# TC37XPD register map
Vendor: Infineon; Series: ATVMC; File version: 100
CPU: other r0p0, little endian, MPU, FPU, vendor SysTick, 4 interrupt priority bits
Registers are 32-bit, read-write, reset 0x0 unless marked. A register's access mark holds for its fields unless they carry their own. Offsets are from the block's base; [hi:lo] are bit positions; {n}, {i} and the like mark numbered series.

## GETH (part 2 of 7)
Base 0xF001D000
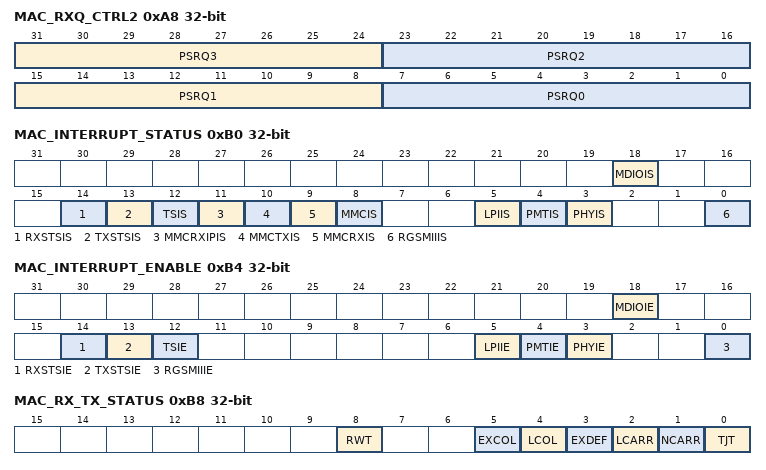
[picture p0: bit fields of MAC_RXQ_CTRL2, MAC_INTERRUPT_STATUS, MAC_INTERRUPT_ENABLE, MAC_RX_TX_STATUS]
0xA8 MAC_RXQ_CTRL2 — MAC Receive Queue Control 2 Register resetvalue={Application Reset:0x0}
  [31:24] PSRQ3 — Priorities Selected in the Receive Queue 3 PSRQ3. This field decides the priorities assigned to Rx Queue 3. All packets with priorities that match the values set in this field are routed to Rx Queue 3. For example if PSRQ3 6 3 are set packets with USP field equal to 3 or 6 are routed to Rx Queue 3. The software must ensure that the content of this field is mutually exclusive to the PSRQ fields for other queues that is the same priority is not mapped to multiple Rx queues. Value After Reset 0x0
  [23:16] PSRQ2 — Priorities Selected in the Receive Queue 2 PSRQ2. This field decides the priorities assigned to Rx Queue 2. All packets with priorities that match the values set in this field are routed to Rx Queue 2. For example if PSRQ2 1 0 are set packets with USP field equal to 1 or 0 are routed to Rx Queue 2. The software must ensure that the content of this field is mutually exclusive to the PSRQ fields for other queues that is the same priority is not mapped to multiple Rx queues. Value After Reset 0x0
  [15:8] PSRQ1 — Priorities Selected in the Receive Queue 1 PSRQ1. This field decides the priorities assigned to Rx Queue 1. All packets with priorities that match the values set in this field are routed to Rx Queue 1. For example if PSRQ1 4 is set packets with USP field equal to 4 are routed to Rx Queue 1. The software must ensure that the content of this field is mutually exclusive to the PSRQ fields for other queues that is the same priority is not mapped to multiple Rx queues. Value After Reset 0x0
  [7:0] PSRQ0 — Priorities Selected in the Receive Queue 0 PSRQ0. This field decides the priorities assigned to Rx Queue 0. All packets with priorities that match the values set in this field are routed to Rx Queue 0. For example if PSRQ0 5 is set packets with USP field equal to 5 are routed to Rx Queue 0. The software must ensure that the content of this field is mutually exclusive to the PSRQ fields for other queues that is the same priority is not mapped to multiple Rx queues. Value After Reset 0x0
0xB0 MAC_INTERRUPT_STATUS ro — MAC Interrupt Status Register resetvalue={Application Reset:0x0}
  [18] MDIOIS — MDIO Interrupt Status MDIOIS. This bit indicates an interrupt event after the completion of MDIO operation. To reset this bit the application has to read this bit Write 1 to this bit when RCWE bit of MAC CSR SW Ctrl register is set. Access restriction applies. Clears on read or write of 1 when RCWE bit in MAC CSR SW Ctrl register is set . Self set to 1 on internal event. Value After Reset 0x0
  [14] RXSTSIS — Receive Status Interrupt RXSTSIS. This bit indicates the status of received packets. This bit is set when the RWT bit is set in the MAC Rx Tx Status register. This bit is cleared when the corresponding interrupt source bit is read or corresponding interrupt source bit is written to 1 when RCWE bit of MAC CSR SW Ctrl register is set in the MAC Rx Tx Status register. Value After Reset 0x0
  [13] TXSTSIS — Transmit Status Interrupt TXSTSIS. This bit indicates the status of transmitted packets. This bit is set when any of the following bits is set in the MAC Rx Tx Status register Excessive Collision EXCOL Late Collision LCOL Excessive Deferral EXDEF Loss of Carrier LCARR No Carrier NCARR Jabber Timeout TJT This bit is cleared when the corresponding interrupt source bit is read or corresponding interrupt source bit is written to 1 when RCWE bit of MAC CSR SW Ctrl register is set in the MAC Rx Tx Status register. Value After Reset 0x0
  [12] TSIS — Timestamp Interrupt Status TSIS. If the Timestamp feature is enabled this bit is set when any of the following conditions is true The system time value is equal to or exceeds the value specified in the Target Time High and Low registers. There is an overflow in the Seconds register. The Target Time Error occurred that is programmed target time already elapsed. In configurations other than EQOS CORE when drop transmit status is enabled in MTL this bit is set when the captured transmit timestamp is updated in the MAC Tx Timestamp Status Nanoseconds and Mac TxTimestamp Status Seconds registers. This bit is cleared when the corresponding interrupt source bit is read or corresponding interrupt source bit is written to 1 when RCWE bit of MAC CSR SW Ctrl register is set in the MAC Timestamp Status register. Value After Reset 0x0
  [11] MMCRXIPIS — MMC Receive Checksum Offload Interrupt Status MMCRXIPIS. This bit is set high when an interrupt is generated in the MMC Receive Checksum Offload Interrupt Register. This bit is cleared when all bits in this interrupt register are cleared. Value After Reset 0x0
  [10] MMCTXIS — MMC Transmit Interrupt Status MMCTXIS. This bit is set high when an interrupt is generated in the MMC Transmit Interrupt Register. This bit is cleared when all bits in this interrupt register are cleared. Value After Reset 0x0
  [9] MMCRXIS — MMC Receive Interrupt Status MMCRXIS. This bit is set high when an interrupt is generated in the MMC Receive Interrupt Register. This bit is cleared when all bits in this interrupt register are cleared. Value After Reset 0x0
  [8] MMCIS — MMC Interrupt Status MMCIS. This bit is set high when Bit 11 Bit 10 or Bit 9 is set high. This bit is cleared only when all these bits are low. Value After Reset 0x0
  [5] LPIIS — LPI Interrupt Status LPIIS. When the Energy Efficient Ethernet feature is enabled this bit is set for any LPI state entry or exit in the MAC Transmitter or Receiver. This bit is cleared when the corresponding interrupt source bit of MAC LPI Control Status register is read or corresponding interrupt source bit of MAC LPI Control Status register is written to 1 when RCWE bit of MAC CSR SW Ctrl register is set . Value After Reset 0x0
  [4] PMTIS — PMT Interrupt Status PMTIS. This bit is set when a Magic packet or Wake on LAN packet is received in the powerdown mode RWKPRCVD and MGKPRCVD bits in MAC PMT Control Status register . This bit is cleared when corresponding interrupt source bit are cleared because of a Read operation to the MAC PMT Control Status register or corresponding interrupt source bit of MAC PMT Control Status register is written to 1 when RCWE bit of MAC CSR SW Ctrl register is set . Value After Reset 0x0
  [3] PHYIS — PHY Interrupt PHYIS. This bit is set when rising edge is detected on the phy intr i input. This bit is cleared when this register is read or this bit is written to 1 when RCWE bit of MAC CSR SW Ctrl register is set . Value After Reset 0x0
  [0] RGSMIIIS — RGMII or SMII Interrupt Status RGSMIIIS. This bit is set because of any change in value of the Link Status of RGMII or SMII interface LNKSTS bit in MAC PHYIF Control Status register . This bit is cleared when the MAC PHYIF Control Status register is read or LNKSTS bit of MAC PHYIF Control Status register is written to 1 when RCWE bit of MAC CSR SW Ctrl register is set . Value After Reset 0x0
0xB4 MAC_INTERRUPT_ENABLE — MAC Interrupt Enable Register resetvalue={Application Reset:0x0}
  [18] MDIOIE — MDIO Interrupt Enable MDIOIE. MDIO Interrupt Enable When this bit is set it enables the assertion of the interrupt when MDIOIS field is set in the MAC Interrupt Status register. Value After Reset 0x0
  [14] RXSTSIE — Receive Status Interrupt Enable RXSTSIE. When this bit is set it enables the assertion of the interrupt signal because of the setting of RXSTSIS bit in the MAC Interrupt Status register. Value After Reset 0x0
  [13] TXSTSIE — Transmit Status Interrupt Enable TXSTSIE. When this bit is set it enables the assertion of the interrupt signal because of the setting of TXSTSIS bit in the MAC Interrupt Status register. Value After Reset 0x0
  [12] TSIE — Timestamp Interrupt Enable TSIE. When this bit is set it enables the assertion of the interrupt signal because of the setting of TSIS bit in MAC Interrupt Status register. Value After Reset 0x0
  [5] LPIIE — LPI Interrupt Enable LPIIE. When this bit is set it enables the assertion of the interrupt signal because of the setting of LPIIS bit in MAC Interrupt Status register. Value After Reset 0x0
  [4] PMTIE — PMT Interrupt Enable PMTIE. When this bit is set it enables the assertion of the interrupt signal because of the setting of PMTIS bit in MAC Interrupt Status register. Value After Reset 0x0
  [3] PHYIE — PHY Interrupt Enable PHYIE. When this bit is set it enables the assertion of the interrupt signal because of the setting of PHYIS bit in MAC Interrupt Status register. Value After Reset 0x0
  [0] RGSMIIIE — RGMII or SMII Interrupt Enable RGSMIIIE. When this bit is set it enables the assertion of the interrupt signal because of the setting of RGSMIIIS bit in MAC Interrupt Status register. Value After Reset 0x0
0xB8 MAC_RX_TX_STATUS ro — MAC Receive Transmit Status Register resetvalue={Application Reset:0x0}
  [8] RWT — Receive Watchdog Timeout RWT. This bit is set when a packet with length greater than 2 048 bytes is received 10 240 bytes when Jumbo Packet mode is enabled and the WD bit is reset in the MAC Configuration register. This bit is set when a packet with length greater than 16 383 bytes is received and the WD bit is set in the MAC Configuration register. Access restriction applies. Clears on read or write of 1 when RCWE bit in MAC CSR SW Ctrl register is set . Self set to 1 on internal event. Value After Reset 0x0
  [5] EXCOL — Excessive Collisions EXCOL. When the DTXSTS bit is set in the MTL Operation Mode register this bit indicates that the transmission aborted after 16 successive collisions while attempting to transmit the current packet. If the DR bit is set in the MAC Configuration register this bit is set after the first collision and the packet transmission is aborted. Access restriction applies. Clears on read or write of 1 when RCWE bit in MAC CSR SW Ctrl register is set . Self set to 1 on internal event. Value After Reset 0x0
  [4] LCOL — Late Collision LCOL. When the DTXSTS bit is set in the MTL Operation Mode register this bit indicates that the packet transmission aborted because a collision occurred after the collision window 64 bytes including Preamble in MII mode 512 bytes including Preamble and Carrier Extension in GMII mode . This bit is not valid if the Underflow error occurs. This bit is reserved in the EQOS CORE configurations and also in configurations with full duplex mode. Access restriction applies. Clears on read or write of 1 when RCWE bit in MAC CSR SW Ctrl register is set . Self set to 1 on internal event. Value After Reset 0x0
  [3] EXDEF — Excessive Deferral EXDEF. When the DTXSTS bit is set in the MTL Operation Mode register and the DC bit is set in the MAC Configuration register this bit indicates that the transmission ended because of excessive deferral of over 24 288 bit times 155 680 in 1000 2500 Mbps mode or when Jumbo packet is enabled . Access restriction applies. Clears on read or write of 1 when RCWE bit in MAC CSR SW Ctrl register is set . Self set to 1 on internal event. Value After Reset 0x0
  [2] LCARR — Loss of Carrier LCARR. When the DTXSTS bit is set in the MTL Operation Mode register this bit indicates that the loss of carrier occurred during packet transmission that is the phy crs i signal was inactive for one or more transmission clock periods during packet transmission. This bit is valid only for packets transmitted without collision. Access restriction applies. Clears on read or write of 1 when RCWE bit in MAC CSR SW Ctrl register is set . Self set to 1 on internal event. Value After Reset 0x0
  [1] NCARR — No Carrier NCARR. When the DTXSTS bit is set in the MTL Operation Mode register this bit indicates that the carrier signal from the PHY is not present at the end of preamble transmission. Access restriction applies. Clears on read or write of 1 when RCWE bit in MAC CSR SW Ctrl register is set . Self set to 1 on internal event. Value After Reset 0x0
  [0] TJT — Transmit Jabber Timeout TJT. This bit indicates that the Transmit Jabber Timer expired which happens when the packet size exceeds 2 048 bytes 10 240 bytes when the Jumbo packet is enabled and JD bit is reset in the MAC Configuration register. This bit is set when the packet size exceeds 16 383 bytes and the JD bit is set in the MAC Configuration register. Access restriction applies. Clears on read or write of 1 when RCWE bit in MAC CSR SW Ctrl register is set . Self set to 1 on internal event. Value After Reset 0x0
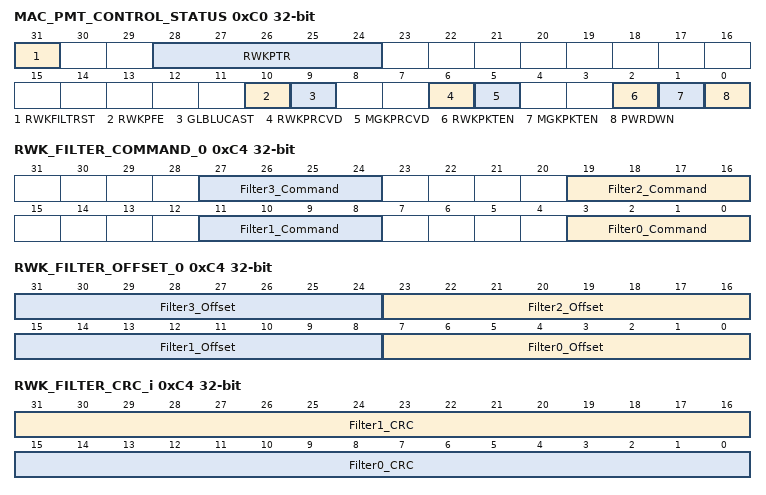
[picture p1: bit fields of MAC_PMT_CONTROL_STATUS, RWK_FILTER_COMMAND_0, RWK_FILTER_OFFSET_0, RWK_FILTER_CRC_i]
0xC0 MAC_PMT_CONTROL_STATUS access per field — MAC PMT Control and Status Register resetvalue={Application Reset:0x0}
  [31] RWKFILTRST rw — Remote Wake Up Packet Filter Register Pointer Reset RWKFILTRST. When this bit is set the remote wake up packet filter register pointer is reset to 3 b000. It is automatically cleared after 1 clock cycle. Access restriction applies. Setting 1 sets. Self cleared. Setting 0 has no effect. Value After Reset 0x0
  [28:24] RWKPTR ro — Remote Wake up FIFO Pointer RWKPTR. This field gives the current value 0 to 7 of the Remote Wake up Packet Filter register pointer. When the value of this pointer is equal to 7 the contents of the Remote Wake up Packet Filter Register are transferred to the clk rx i domain when a Write occurs to that register. Value After Reset 0x0
  [10] RWKPFE rw — Remote Wake up Packet Forwarding Enable RWKPFE. When this bit is set along with RWKPKTEN the MAC receiver drops all received frames until it receives the expected Wake up frame. All frames after that event including the received wake up frame are forwarded to application. This bit is then self cleared on receiving the wake up packet. The application can also clear this bit before the expected wake up frame is received. In such cases the MAC reverts to the default behavior where packets received are forwarded to the application. This bit must only be set when RWKPKTEN is set high and PWRDWN is set low. The setting of this bit has no effect when PWRDWN is set high. Note If Magic Packet Enable and Wake Up Frame Enable are both set along with setting of this bit and Magic Packet is received prior to wake up frame this bit is self cleared on receiving Magic Packet the received Magic packet is dropped and all frames after received Magic Packet are forwarded to application. Access restriction applies. Setting 1 sets. Self cleared. Setting 0 has no effect. Value After Reset 0x0
  [9] GLBLUCAST rw — Global Unicast GLBLUCAST. When this bit set any unicast packet filtered by the MAC DAF address recognition is detected as a remote wake up packet. Value After Reset 0x0
  [6] RWKPRCVD ro — Remote Wake Up Packet Received RWKPRCVD. When this bit is set it indicates that the power management event is generated because of the reception of a remote wake up packet. This bit is cleared when this register is read. Access restriction applies. Clears on read or write of 1 when RCWE bit in MAC CSR SW Ctrl register is set . Self set to 1 on internal event. Value After Reset 0x0
  [5] MGKPRCVD ro — Magic Packet Received MGKPRCVD. When this bit is set it indicates that the power management event is generated because of the reception of a magic packet. This bit is cleared when this register is read. Access restriction applies. Clears on read or write of 1 when RCWE bit in MAC CSR SW Ctrl register is set . Self set to 1 on internal event. Value After Reset 0x0
  [2] RWKPKTEN rw — Remote Wake Up Packet Enable RWKPKTEN. When this bit is set a power management event is generated when the MAC receives a remote wake up packet. Value After Reset 0x0
  [1] MGKPKTEN rw — Magic Packet Enable MGKPKTEN. When this bit is set a power management event is generated when the MAC receives a magic packet. Value After Reset 0x0
  [0] PWRDWN rw — Power Down PWRDWN. When this bit is set the MAC receiver drops all received packets until it receives the expected magic packet or remote wake up packet. This bit is then self cleared and the power down mode is disabled. The software can clear this bit before the expected magic packet or remote wake up packet is received. The packets received by the MAC after this bit is cleared are forwarded to the application. This bit must only be set when the Magic Packet Enable Global Unicast or Remote Wake Up Packet Enable bit is set high. Note You can gate off the CSR clock during the power down mode. However when the CSR clock is gated off you cannot perform any read or write operations on this register. Therefore the Software cannot clear this bit. Access restriction applies. Setting 1 sets. Self cleared. Setting 0 has no effect. Value After Reset 0x0
0xC4 MAC_RWK_PACKET_FILTER — MAC Wake up Packet Filter Register resetvalue={Application Reset:0x0}
  [31:0] WKUPFRMFTR — RWK Packet Filter WKUPFRMFTR. This field contains the various controls of RWK Packet filter. Value After Reset 0x0
0xC4 RWK_FILTER_COMMAND_0 (alternate view of MAC_RWK_PACKET_FILTER) — MAC Wake up Filter Command 0 Register resetvalue={Application Reset:0x0}
  [8n+3:8n] Filter{n}_Command (n=0..3) — Filter{n} Command. The 4 bit filter command controls the filter operation. Bit 3 specifies the address type defining the destination address type of the pattern. When the bit is set the pattern applies to only multicast packets when the bit is reset the pattern applies only to unicast packet. Bit 2 Inverse Mode when set reverses the logic of the CRC16 hash function signal to reject a packet with matching CRC 16 value. Bit 2 along with Bit 1 allows a MAC to reject a subset of remote wake up packets by creating filter logic such as Pattern 1 AND NOT Pattern 2 . Bit 1 And Previous implements the Boolean logic. When set the result of the current entry is logically ANDed with the result of the previous filter. This AND logic allows a filter pattern longer than 32 bytes by splitting the mask among two three or four filters. This depends on the number of filters that have the And Previous bit set. Bit 0 is the enable for filter. If Bit 0 is not set filter is disabled. Value After Reset 0x0
0xC4 RWK_FILTER_OFFSET_0 (alternate view of MAC_RWK_PACKET_FILTER) — MAC Wake up Filter Offset 0 Register resetvalue={Application Reset:0x0}
  [8n+7:8n] Filter{n}_Offset (n=0..3) — Filter{n} Offset. This filter offset defines the offset within the packet from which the filter examines the packets. This 8 bit pattern offset is the offset for the filter first byte to be examined. The minimum allowed offset is 12 which refers to the 13th byte of the packet. The offset value 0 refers to the first byte of the packet. Value After Reset 0x0
0xC4 RWK_FILTER_CRC_i (alternate view of MAC_RWK_PACKET_FILTER) — MAC Wake up Filter CRC Register resetvalue={Application Reset:0x0}
  [31:16] Filter1_CRC — Filter1 CRC. This filter CRC 16 contains the CRC 16 value of the pattern. The 16 bit CRC calculation uses the following polynomial G x x 16 x 15 x 2 1 Value After Reset 0x0
  [15:0] Filter0_CRC — Filter0 CRC. This filter CRC 16 contains the CRC 16 value of the pattern. The 16 bit CRC calculation uses the following polynomial G x x 16 x 15 x 2 1 Value After Reset 0x0
0xC4 RWK_FILTER_BYTE_MASK_i (alternate view of MAC_RWK_PACKET_FILTER) — MAC Wake up Filter Byte Mask register resetvalue={Application Reset:0x0}
  [31:0] Filteri_Byte_Mask — Filter 32 bit Mask Filteri Byte Mask. Each bit in this mask corresponds to one byte in the detected packet. If the bit is 1 the corresponding byte is taken into the CRC16 calculation. Value After Reset 0x0
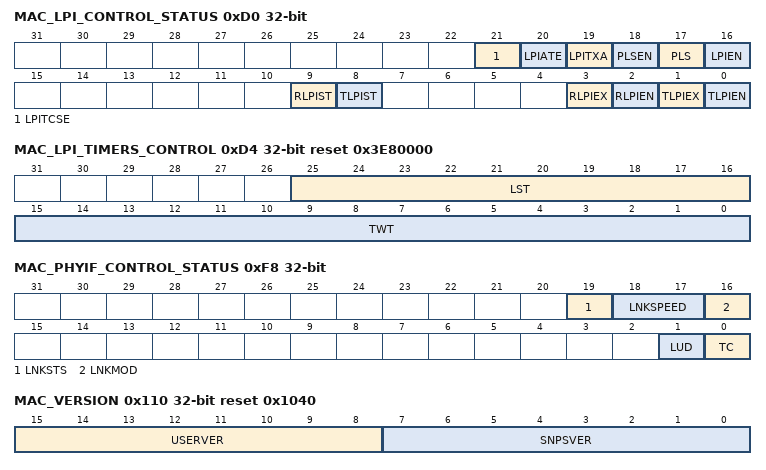
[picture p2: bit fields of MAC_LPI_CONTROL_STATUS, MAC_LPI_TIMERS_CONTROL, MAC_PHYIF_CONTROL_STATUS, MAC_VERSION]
0xD0 MAC_LPI_CONTROL_STATUS access per field — MAC LPI Control and Status Register resetvalue={Application Reset:0x0}
  [21] LPITCSE rw — LPI Tx Clock Stop Enable LPITCSE. When this bit is set the MAC asserts sbd tx clk gating ctrl o signal high after it enters Tx LPI mode to indicate that the Tx clock to MAC can be stopped. When this bit is reset the MAC does not assert sbd tx clk gating ctrl o signal high after it enters Tx LPI mode. If RGMII Interface is selected the Tx clock is required for transmitting the LPI pattern. The Tx Clock cannot be gated and so the LPITCSE bit cannot be programmed. Value After Reset 0x0
  [20] LPIATE rw — LPI Timer Enable LPIATE. This bit controls the automatic entry of the MAC Transmitter into and exit out of the LPI state. When LPIATE LPITXA and LPIEN bits are set the MAC Transmitter enters LPI state only when the complete MAC TX data path is IDLE for a period indicated by the MAC LPI Entry Timer register. After entering LPI state if the data path becomes non IDLE due to a new packet being accepted for transmission the Transmitter exits LPI state but does not clear LPIEN bit. This enables the re entry into LPI state when it is IDLE again. When LPIATE is 0 the LPI Auto timer is disabled and MAC Transmitter enters LPI state based on the settings of LPITXA and LPIEN bit descriptions. Value After Reset 0x0
  [19] LPITXA rw — LPI Tx Automate LPITXA. This bit controls the behavior of the MAC when it is entering or coming out of the LPI mode on the Transmit side. This bit is not functional in the EQOS CORE configurations in which the Tx clock gating is done during the LPI mode. If the LPITXA and LPIEN bits are set to 1 the MAC enters the LPI mode only after all outstanding packets in the core and pending packets in the application interface have been transmitted. The MAC comes out of the LPI mode when the application sends any packet for transmission or the application issues a Tx FIFO Flush command. In addition the MAC automatically clears the LPIEN bit when it exits the LPI state. If Tx FIFO Flush is set in the FTQ bit of MTL TxQ0 Operation Mode register when the MAC is in the LPI mode it exits the LPI mode. When this bit is 0 the LPIEN bit directly controls behavior of the MAC when it is entering or coming out of the LPI mode. Value After Reset 0x0
  [18] PLSEN rw — PHY Link Status Enable PLSEN. This bit enables the link status received on the RGMII SGMII or SMII Receive paths to be used for activating the LPI LS TIMER. When this bit is set the MAC uses the link status bits of the MAC PHYIF Control Status register and the PLS bit for the LPI LS Timer trigger. When this bit is reset the MAC ignores the link status bits of the MAC PHYIF Control Status register and takes only the PLS bit. Value After Reset 0x0
  [17] PLS rw — PHY Link Status PLS. This bit indicates the link status of the PHY. The MAC Transmitter asserts the LPI pattern only when the link status is up OKAY at least for the time indicated by the LPI LS TIMER. When this bit is set the link is considered to be okay UP and when this bit is reset the link is considered to be down. Value After Reset 0x0
  [16] LPIEN rw — LPI Enable LPIEN. When this bit is set it instructs the MAC Transmitter to enter the LPI state. When this bit is reset it instructs the MAC to exit the LPI state and resume normal transmission. This bit is cleared when the LPITXA bit is set and the MAC exits the LPI state because of the arrival of a new packet for transmission. Value After Reset 0x0
  [9] RLPIST ro — Receive LPI State RLPIST. When this bit is set it indicates that the MAC is receiving the LPI pattern on the GMII or MII interface. Value After Reset 0x0
  [8] TLPIST ro — Transmit LPI State TLPIST. When this bit is set it indicates that the MAC is transmitting the LPI pattern on the GMII or MII interface. Value After Reset 0x0
  [3] RLPIEX ro — Receive LPI Exit RLPIEX. When this bit is set it indicates that the MAC Receiver has stopped receiving the LPI pattern on the GMII or MII interface exited the LPI state and resumed the normal reception. This bit is cleared by a read into this register or this bit is written to 1 when RCWE bit in MAC CSR SW Ctrl register is set . Note This bit may not be set if the MAC stops receiving the LPI pattern for a very short duration such as less than three clock cycles of CSR clock. Value After Reset 0x0
  [2] RLPIEN ro — Receive LPI Entry RLPIEN. When this bit is set it indicates that the MAC Receiver has received an LPI pattern and entered the LPI state. This bit is cleared by a read into this register or this bit is written to 1 when RCWE bit in MAC CSR SW Ctrl register is set . Note This bit may not be set if the MAC stops receiving the LPI pattern for a very short duration such as less than three clock cycles of CSR clock. Value After Reset 0x0
  [1] TLPIEX ro — Transmit LPI Exit TLPIEX. When this bit is set it indicates that the MAC transmitter exited the LPI state after the application cleared the LPIEN bit and the LPI TW Timer has expired. This bit is cleared by a read into this register or this bit is written to 1 when RCWE bit in MAC CSR SW Ctrl register is set . Value After Reset 0x0
  [0] TLPIEN ro — Transmit LPI Entry TLPIEN. When this bit is set it indicates that the MAC Transmitter has entered the LPI state because of the setting of the LPIEN bit. This bit is cleared by a read into this register or this bit is written to 1 when RCWE bit in MAC CSR SW Ctrl register is set . Value After Reset 0x0
0xD4 MAC_LPI_TIMERS_CONTROL reset 0x3E80000 — MAC LPI Timers Control Register resetvalue={Application Reset:0x3E80000}
  [25:16] LST — LPI LS Timer LST. This field specifies the minimum time in milliseconds for which the link status from the PHY should be up OKAY before the LPI pattern can be transmitted to the PHY. The MAC does not transmit the LPI pattern even when the LPIEN bit is set unless the LPI LS Timer reaches the programmed terminal count. The default value of the LPI LS Timer is 1000 1 sec as defined in the IEEE standard. Value After Reset 0x3e8
  [15:0] TWT — LPI TW Timer TWT. This field specifies the minimum time in microseconds for which the MAC waits after it stops transmitting the LPI pattern to the PHY and before it resumes the normal transmission. The TLPIEX status bit is set after the expiry of this timer. Value After Reset 0x0
0xD8 MAC_LPI_ENTRY_TIMER — MAC LPI Entry Timer Register resetvalue={Application Reset:0x0}
  [19:3] LPIET — LPI Entry Timer LPIET. This field specifies the time in microseconds the MAC waits to enter LPI mode after it has transmitted all the frames. This field is valid and used only when LPITE and LPITXA are set to 1. Bits 2 0 are read only so that the granularity of this timer is in steps of 8 micro seconds. Value After Reset 0x0
0xDC MAC_1US_TIC_COUNTER reset 0x63 — MAC One Microsecond Tic Counter Register resetvalue={Application Reset:0x63}
  [11:0] TIC_1US_CNTR — 1US TIC Counter TIC 1US CNTR. The application must program this counter so that the number of clock cycles of CSR clock is 1us. Subtract 1 from the value before programming . For example if the CSR clock is 100MHz then this field needs to be programmed to value 100 1 99 which is 0x63 . This is required to generate the 1US events that are used to update some of the EEE related counters. Value After Reset 0x63
0xF8 MAC_PHYIF_CONTROL_STATUS access per field — MAC PHY Interface Control and Status Register resetvalue={Application Reset:0x0}
  [19] LNKSTS ro — Link Status LNKSTS. This bit indicates whether the link is up 1 b1 or down 1 b0 . Value After Reset 0x0
  [18:17] LNKSPEED ro — Link Speed LNKSPEED. This bit indicates the current speed of the link Value After Reset 0x0
  [16] LNKMOD ro — Link Mode LNKMOD. This bit indicates the current mode of operation of the link Value After Reset 0x0
  [1] LUD rw — Link Up or Down LUD. This bit indicates whether the link is up or down during transmission of configuration in the RGMII SGMII or SMII interface Value After Reset 0x0
  [0] TC rw — Transmit Configuration in RGMII SGMII or SMII TC. When set this bit enables the transmission of duplex mode link speed and link up or down information to the PHY in the RGMII SMII or SGMII port. When this bit is reset no such information is driven to the PHY. The details of this feature are provided in the following sections Reduced Gigabit Media Independent Interface Serial Media Independent Interface Serial Gigabit Media Independent Interface Value After Reset 0x0
0x110 MAC_VERSION ro reset 0x1040 (reset mask 0xFFFFFFED) — MAC Version Register resetvalue={Application Reset:0x1042,Application Reset:0x1050}
  [15:8] USERVER — User defined Version configured with coreConsultant USERVER. Value After Reset 0x10
  [7:0] SNPSVER — Synopsys defined Version SNPSVER. IP Version
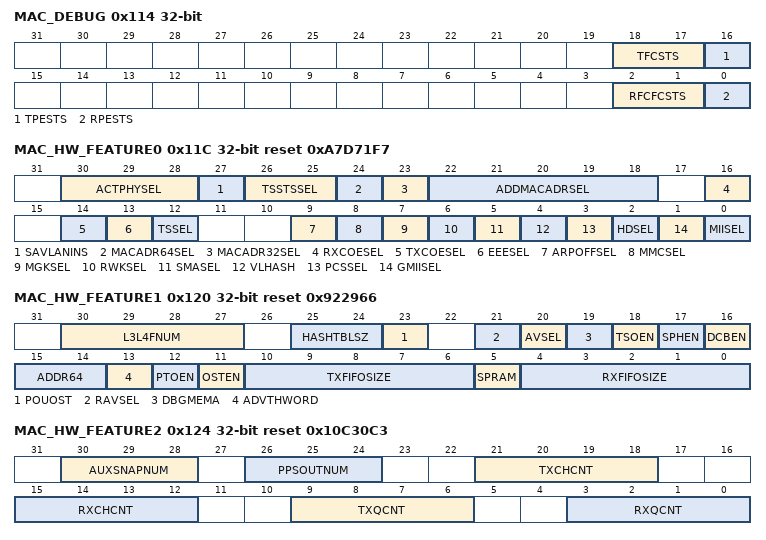
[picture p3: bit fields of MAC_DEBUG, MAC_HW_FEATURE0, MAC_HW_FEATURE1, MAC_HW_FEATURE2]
0x114 MAC_DEBUG ro — MAC Debug Register resetvalue={Application Reset:0x0}
  [18:17] TFCSTS — MAC Transmit Packet Controller Status TFCSTS. This field indicates the state of the MAC Transmit Packet Controller module Status of the previous packet OR IPG or backoff period to be over Value After Reset 0x0
  [16] TPESTS — MAC GMII or MII Transmit Protocol Engine Status TPESTS. When this bit is set it indicates that the MAC GMII or MII transmit protocol engine is actively transmitting data and it is not in the Idle state. Value After Reset 0x0
  [2:1] RFCFCSTS — MAC Receive Packet Controller FIFO Status RFCFCSTS. When this bit is set this field indicates the active state of the small FIFO Read and Write controllers of the MAC Receive Packet Controller module. Value After Reset 0x0
  [0] RPESTS — MAC GMII or MII Receive Protocol Engine Status RPESTS. When this bit is set it indicates that the MAC GMII or MII receive protocol engine is actively receiving data and it is not in the Idle state. Value After Reset 0x0
0x11C MAC_HW_FEATURE0 ro reset 0xA7D71F7 — MAC Hardware Feature Register 0 resetvalue={Application Reset:0x0A7D71F7}
  [30:28] ACTPHYSEL — Active PHY Selected ACTPHYSEL. When you have multiple PHY interfaces in your configuration this field indicates the sampled value of phy intf sel i during reset de assertion All Others Reserved Value After Reset 0x0
  [27] SAVLANINS — Source Address or VLAN Insertion Enable SAVLANINS. This bit is set to 1 when the Enable SA and VLAN Insertion on Tx option is selected Value After Reset 0x1
  [26:25] TSSTSSEL — Timestamp System Time Source TSSTSSEL. This bit indicates the source of the Timestamp system time This bit is set to 1 when the Enable IEEE 1588 Timestamp Support option is selected Value After Reset 0x1
  [24] MACADR64SEL — MAC Addresses 64 127 Selected MACADR64SEL. This bit is set to 1 when the Enable Additional 64 MAC Address Registers 64 127 option is selected Value After Reset 0x0
  [23] MACADR32SEL — MAC Addresses 32 63 Selected MACADR32SEL. This bit is set to 1 when the Enable Additional 32 MAC Address Registers 32 63 option is selected Value After Reset 0x0
  [22:18] ADDMACADRSEL — MAC Addresses 1 31 Selected ADDMACADRSEL. This bit is set to 1 when the Enable Additional 1 31 MAC Address Registers option is selected Value After Reset 0x1f
  [16] RXCOESEL — Receive Checksum Offload Enabled RXCOESEL. This bit is set to 1 when the Enable Receive TCP IP Checksum Check option is selected Value After Reset 0x1
  [14] TXCOESEL — Transmit Checksum Offload Enabled TXCOESEL. This bit is set to 1 when the Enable Transmit TCP IP Checksum Insertion option is selected Value After Reset 0x1
  [13] EEESEL — Energy Efficient Ethernet Enabled EEESEL. This bit is set to 1 when the Enable Energy Efficient Ethernet EEE option is selected Value After Reset 0x1
  [12] TSSEL — IEEE 1588 2008 Timestamp Enabled TSSEL. This bit is set to 1 when the Enable IEEE 1588 Timestamp Support option is selected Value After Reset 0x1
  [9] ARPOFFSEL — ARP Offload Enabled ARPOFFSEL. This bit is set to 1 when the Enable IPv4 ARP Offload option is selected Value After Reset 0x0
  [8] MMCSEL — RMON Module Enable MMCSEL. This bit is set to 1 when the Enable MAC Management Counters MMC option is selected Value After Reset 0x1
  [7] MGKSEL — PMT Magic Packet Enable MGKSEL. This bit is set to 1 when the Enable Magic Packet Detection option is selected Value After Reset 0x1
  [6] RWKSEL — PMT Remote Wake up Packet Enable RWKSEL. This bit is set to 1 when the Enable Remote Wake Up Packet Detection option is selected Value After Reset 0x1
  [5] SMASEL — SMA MDIO Interface SMASEL. This bit is set to 1 when the Enable Station Management MDIO Interface option is selected Value After Reset 0x1
  [4] VLHASH — VLAN Hash Filter Selected VLHASH. This bit is set to 1 when the Enable VLAN Hash Table Based Filtering option is selected Value After Reset 0x1
  [3] PCSSEL — PCS Registers TBI SGMII or RTBI PHY interface PCSSEL. This bit is set to 1 when the TBI SGMII or RTBI PHY interface option is selected Value After Reset 0x0
  [2] HDSEL — Half duplex Support HDSEL. This bit is set to 1 when the half duplex mode is selected Value After Reset 0x1
  [1] GMIISEL — 1000 Mbps Support GMIISEL. This bit is set to 1 when 1000 Mbps is selected as the Mode of Operation Value After Reset 0x1
  [0] MIISEL — 10 or 100 Mbps Support MIISEL. This bit is set to 1 when 10 100 Mbps is selected as the Mode of Operation Value After Reset 0x1
0x120 MAC_HW_FEATURE1 ro reset 0x922966 — MAC Hardware Feature Register 1 resetvalue={Application Reset:0x0922966}
  [30:27] L3L4FNUM — Total number of L3 or L4 Filters L3L4FNUM. This field indicates the total number of L3 or L4 filters LOST SEQUENCE DEFINITION Value After Reset 0x0
  [25:24] HASHTBLSZ — Hash Table Size HASHTBLSZ. This field indicates the size of the hash table Value After Reset 0x0
  [23] POUOST — One Step for PTP over UDP IP Feature Enable POUOST. This bit is set to 1 when the Enable One step timestamp for PTP over UDP IP feature is selected. Value After Reset 0x1
  [21] RAVSEL — Rx Side Only AV Feature Enable RAVSEL. This bit is set to 1 when the Enable Audio Video Bridging option on Rx Side Only is selected. Value After Reset 0x0
  [20] AVSEL — AV Feature Enable AVSEL. This bit is set to 1 when the Enable Audio Video Bridging option is selected. Value After Reset 0x1
  [19] DBGMEMA — DMA Debug Registers Enable DBGMEMA. This bit is set to 1 when the Debug Mode Enable option is selected Value After Reset 0x0
  [18] TSOEN — TCP Segmentation Offload Enable TSOEN. This bit is set to 1 when the Enable TCP Segmentation Offloading for TCP IP Packets option is selected Value After Reset 0x0
  [17] SPHEN — Split Header Feature Enable SPHEN. This bit is set to 1 when the Enable Split Header Structure option is selected Value After Reset 0x1
  [16] DCBEN — DCB Feature Enable DCBEN. This bit is set to 1 when the Enable Data Center Bridging option is selected Value After Reset 0x0
  [15:14] ADDR64 — Address Width. ADDR64. This field indicates the configured address width Value After Reset 0x0
  [13] ADVTHWORD — IEEE 1588 High Word Register Enable ADVTHWORD. This bit is set to 1 when the Add IEEE 1588 Higher Word Register option is selected Value After Reset 0x1
  [12] PTOEN — PTP Offload Enable PTOEN. This bit is set to 1 when the Enable PTP Timestamp Offload Feature is selected. Value After Reset 0x0
  [11] OSTEN — One Step Timestamping Enable OSTEN. This bit is set to 1 when the Enable One Step Timestamp Feature is selected. Value After Reset 0x1
  [10:6] TXFIFOSIZE — MTL Transmit FIFO Size TXFIFOSIZE. This field contains the configured value of MTL Tx FIFO in bytes expressed as Log to base 2 minus 7 that is Log2 TXFIFO SIZE 7 01011 11111 Reserved Value After Reset 0x5
  [5] SPRAM — Single Port RAM Enable SPRAM. This bit is set to 1 when the Use single port RAM Feature is selected. Value After Reset 0x1
  [4:0] RXFIFOSIZE — MTL Receive FIFO Size RXFIFOSIZE. This field contains the configured value of MTL Rx FIFO in bytes expressed as Log to base 2 minus 7 that is Log2 RXFIFO SIZE 7 01100 11111 Reserved Value After Reset 0x6
0x124 MAC_HW_FEATURE2 ro reset 0x10C30C3 — MAC Hardware Feature Register 2 resetvalue={Application Reset:0x10C30C3}
  [30:28] AUXSNAPNUM — Number of Auxiliary Snapshot Inputs AUXSNAPNUM. This field indicates the number of auxiliary snapshot inputs 101 111 Reserved Value After Reset 0x0
  [26:24] PPSOUTNUM — Number of PPS Outputs PPSOUTNUM. This field indicates the number of PPS outputs 101 111 Reserved Value After Reset 0x1
  [21:18] TXCHCNT — Number of DMA Transmit Channels TXCHCNT. This field indicates the number of DMA Transmit channels LOST SEQUENCE DEFINITION Value After Reset 0x3
  [15:12] RXCHCNT — Number of DMA Receive Channels RXCHCNT. This field indicates the number of DMA Receive channels LOST SEQUENCE DEFINITION Value After Reset 0x3
  [9:6] TXQCNT — Number of MTL Transmit Queues TXQCNT. This field indicates the number of MTL Transmit queues LOST SEQUENCE DEFINITION Value After Reset 0x3
  [3:0] RXQCNT — Number of MTL Receive Queues RXQCNT. This field indicates the number of MTL Receive queues LOST SEQUENCE DEFINITION Value After Reset 0x3
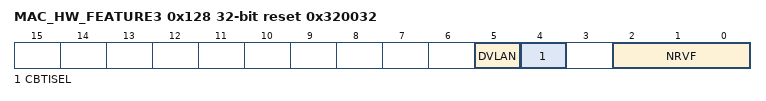
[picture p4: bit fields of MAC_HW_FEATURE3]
0x128 MAC_HW_FEATURE3 ro reset 0x320032 — MAC Hardware Feature Register 3 resetvalue={Application Reset:0x320032}
  [5] DVLAN — DVLAN. Value After Reset 0x1
  [4] CBTISEL — Queue Channel based VLAN tag insertion on Tx Enable CBTISEL. This bit is set to 1 when the Enable Queue Channel based VLAN tag insertion on Tx Feature is selected. Value After Reset 0x1
  [2:0] NRVF — Number of Extended VLAN Tag Filters Enabled NRVF. This field indicates the Number of Extended VLAN Tag Filters selected 110 111 Reserved Value After Reset 0x2
